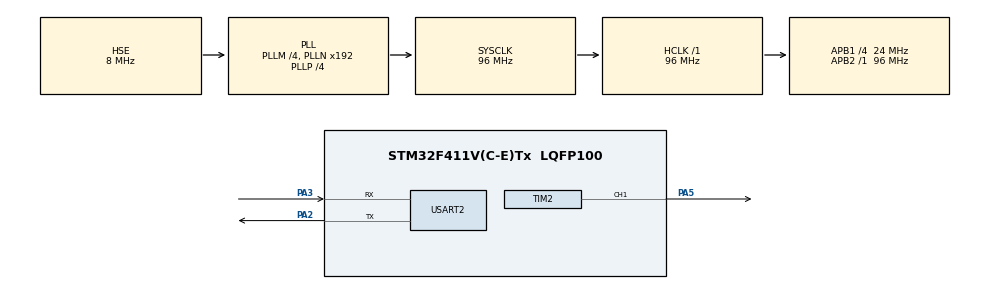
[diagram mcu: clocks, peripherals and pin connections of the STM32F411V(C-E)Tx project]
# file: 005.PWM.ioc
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Mcu.Family=STM32F4
Mcu.Name=STM32F411V(C-E)Tx
Mcu.Package=LQFP100
NVIC.PriorityGroup=NVIC_PRIORITYGROUP_0
NVIC.USART2_IRQn=true\:0\:0\:false\:false\:true\:true\:true\:true
PA13.Mode=Serial_Wire
PA13.Signal=SYS_JTMS-SWDIO
PA14.Mode=Serial_Wire
PA14.Signal=SYS_JTCK-SWCLK
PA2.Mode=Asynchronous
PA2.Signal=USART2_TX
PA3.Mode=Asynchronous
PA3.Signal=USART2_RX
PA5.Signal=S_TIM2_CH1_ETR
PC14-OSC32_IN.Mode=LSE-External-Oscillator
PC14-OSC32_IN.Signal=RCC_OSC32_IN
PC15-OSC32_OUT.Mode=LSE-External-Oscillator
PC15-OSC32_OUT.Signal=RCC_OSC32_OUT
PH0\ -\ OSC_IN.Mode=HSE-External-Oscillator
PH0\ -\ OSC_IN.Signal=RCC_OSC_IN
PH1\ -\ OSC_OUT.Mode=HSE-External-Oscillator
PH1\ -\ OSC_OUT.Signal=RCC_OSC_OUT
ProjectManager.HeapSize=0x200
ProjectManager.StackSize=0x400
ProjectManager.TargetToolchain=STM32CubeIDE
RCC.48MHZClocksFreq_Value=48000000
RCC.AHBFreq_Value=96000000
RCC.APB1CLKDivider=RCC_HCLK_DIV4
RCC.APB1Freq_Value=24000000
RCC.APB1TimFreq_Value=48000000
RCC.APB2Freq_Value=96000000
RCC.APB2TimFreq_Value=96000000
RCC.CortexFreq_Value=96000000
RCC.HCLKFreq_Value=96000000
RCC.HSE_VALUE=8000000
RCC.HSI_VALUE=16000000
RCC.PLLI2SM=5
RCC.PLLI2SN=200
RCC.PLLM=4
RCC.PLLP=RCC_PLLP_DIV4
RCC.PLLQ=8
RCC.PLLSourceVirtual=RCC_PLLSOURCE_HSE
RCC.SYSCLKFreq_VALUE=96000000
RCC.SYSCLKSource=RCC_SYSCLKSOURCE_PLLCLK
RCC.VCOOutputFreq_Value=384000000
SH.S_TIM2_CH1_ETR.0=TIM2_CH1,PWM Generation1 CH1
TIM2.Channel-PWM\ Generation1\ CH1=TIM_CHANNEL_1
TIM2.Period=19999
TIM2.Prescaler=71
USART2.VirtualMode=VM_ASYNC
board=STM32F411E-DISCO

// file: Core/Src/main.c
/* USER CODE BEGIN Header */
/**
  ******************************************************************************
  * @file           : main.c
  * @brief          : Main program body
  ******************************************************************************
  * @attention
  *
  * Copyright (c) 2025 STMicroelectronics.
  * All rights reserved.
  *
  * This software is licensed under terms that can be found in the LICENSE file
  * in the root directory of this software component.
  * If no LICENSE file comes with this software, it is provided AS-IS.
  *
  ******************************************************************************
  */
/* USER CODE END Header */
#include "main.h"

/* USER CODE BEGIN Includes */
#include <string.h>
#include <stdlib.h>
#include <stdio.h>
/* USER CODE END Includes */

TIM_HandleTypeDef htim2;

UART_HandleTypeDef huart2;

/* USER CODE BEGIN PV */
char rxBuffer[10];
uint8_t rxIndex = 0;
uint8_t rxData;
/* USER CODE END PV */

void SystemClock_Config(void);
static void MX_GPIO_Init(void);
static void MX_TIM2_Init(void);
static void MX_USART2_UART_Init(void);

int main(void)
{

  /* MCU Configuration--------------------------------------------------------*/

  /* Reset of all peripherals, Initializes the Flash interface and the Systick. */
  HAL_Init();

  /* Configure the system clock */
  SystemClock_Config();

  /* Initialize all configured peripherals */
  MX_GPIO_Init();
  MX_TIM2_Init();
  MX_USART2_UART_Init();
  /* USER CODE BEGIN 2 */
  HAL_TIM_PWM_Start(&htim2, TIM_CHANNEL_1);
  HAL_UART_Receive_IT(&huart2, &rxData, 1);  /* USER CODE END 2 */

  /* Infinite loop */
  while (1)
  {

  }
}

void SystemClock_Config(void)
{
  RCC_OscInitTypeDef RCC_OscInitStruct = {0};
  RCC_ClkInitTypeDef RCC_ClkInitStruct = {0};

  /** Configure the main internal regulator output voltage
  */
  __HAL_RCC_PWR_CLK_ENABLE();
  __HAL_PWR_VOLTAGESCALING_CONFIG(PWR_REGULATOR_VOLTAGE_SCALE1);

  /** Initializes the RCC Oscillators according to the specified parameters
  * in the RCC_OscInitTypeDef structure.
  */
  RCC_OscInitStruct.OscillatorType = RCC_OSCILLATORTYPE_HSE;
  RCC_OscInitStruct.HSEState = RCC_HSE_ON;
  RCC_OscInitStruct.PLL.PLLState = RCC_PLL_ON;
  RCC_OscInitStruct.PLL.PLLSource = RCC_PLLSOURCE_HSE;
  RCC_OscInitStruct.PLL.PLLM = 4;
  RCC_OscInitStruct.PLL.PLLN = 192;
  RCC_OscInitStruct.PLL.PLLP = RCC_PLLP_DIV4;
  RCC_OscInitStruct.PLL.PLLQ = 8;
  if (HAL_RCC_OscConfig(&RCC_OscInitStruct) != HAL_OK)
  {
    Error_Handler();
  }

  /** Initializes the CPU, AHB and APB buses clocks
  */
  RCC_ClkInitStruct.ClockType = RCC_CLOCKTYPE_HCLK|RCC_CLOCKTYPE_SYSCLK
                              |RCC_CLOCKTYPE_PCLK1|RCC_CLOCKTYPE_PCLK2;
  RCC_ClkInitStruct.SYSCLKSource = RCC_SYSCLKSOURCE_PLLCLK;
  RCC_ClkInitStruct.AHBCLKDivider = RCC_SYSCLK_DIV1;
  RCC_ClkInitStruct.APB1CLKDivider = RCC_HCLK_DIV4;
  RCC_ClkInitStruct.APB2CLKDivider = RCC_HCLK_DIV1;

  if (HAL_RCC_ClockConfig(&RCC_ClkInitStruct, FLASH_LATENCY_3) != HAL_OK)
  {
    Error_Handler();
  }
}

static void MX_TIM2_Init(void)
{

  TIM_MasterConfigTypeDef sMasterConfig = {0};
  TIM_OC_InitTypeDef sConfigOC = {0};

  htim2.Instance = TIM2;
  htim2.Init.Prescaler = 71;
  htim2.Init.CounterMode = TIM_COUNTERMODE_UP;
  htim2.Init.Period = 19999;
  htim2.Init.ClockDivision = TIM_CLOCKDIVISION_DIV1;
  htim2.Init.AutoReloadPreload = TIM_AUTORELOAD_PRELOAD_DISABLE;
  if (HAL_TIM_PWM_Init(&htim2) != HAL_OK)
  {
    Error_Handler();
  }
  sMasterConfig.MasterOutputTrigger = TIM_TRGO_RESET;
  sMasterConfig.MasterSlaveMode = TIM_MASTERSLAVEMODE_DISABLE;
  if (HAL_TIMEx_MasterConfigSynchronization(&htim2, &sMasterConfig) != HAL_OK)
  {
    Error_Handler();
  }
  sConfigOC.OCMode = TIM_OCMODE_PWM1;
  sConfigOC.Pulse = 0;
  sConfigOC.OCPolarity = TIM_OCPOLARITY_HIGH;
  sConfigOC.OCFastMode = TIM_OCFAST_DISABLE;
  if (HAL_TIM_PWM_ConfigChannel(&htim2, &sConfigOC, TIM_CHANNEL_1) != HAL_OK)
  {
    Error_Handler();
  }
  HAL_TIM_MspPostInit(&htim2);

}

static void MX_USART2_UART_Init(void)
{

  huart2.Instance = USART2;
  huart2.Init.BaudRate = 115200;
  huart2.Init.WordLength = UART_WORDLENGTH_8B;
  huart2.Init.StopBits = UART_STOPBITS_1;
  huart2.Init.Parity = UART_PARITY_NONE;
  huart2.Init.Mode = UART_MODE_TX_RX;
  huart2.Init.HwFlowCtl = UART_HWCONTROL_NONE;
  huart2.Init.OverSampling = UART_OVERSAMPLING_16;
  if (HAL_UART_Init(&huart2) != HAL_OK)
  {
    Error_Handler();
  }

}

static void MX_GPIO_Init(void)
{

  /* GPIO Ports Clock Enable */
  __HAL_RCC_GPIOC_CLK_ENABLE();
  __HAL_RCC_GPIOH_CLK_ENABLE();
  __HAL_RCC_GPIOA_CLK_ENABLE();

}

/* USER CODE BEGIN 4 */
void HAL_UART_RxCpltCallback(UART_HandleTypeDef *huart)
{
    static char buffer[10];
    static uint8_t idx = 0;
    uint8_t rxData;
    if (huart->Instance == USART2)
    {
        if (rxData != '\n')
        {
            buffer[idx++] = rxData;
        }
        else
        {
            buffer[idx] = '\0';
            uint16_t pwmVal = atoi(buffer); // C# tarafından gelen string değeri sayıya çevir

            if (pwmVal >= 500 && pwmVal <= 2500)
            {
                __HAL_TIM_SET_COMPARE(&htim2, TIM_CHANNEL_1, pwmVal);
            }

            idx = 0;
            memset(buffer, 0, sizeof(buffer));
        }
        HAL_UART_Receive_IT(&huart2, &rxData, 1);
    }
}
/* USER CODE END 4 */

void Error_Handler(void)
{
  __disable_irq();
  while (1)
  {
  }
}
